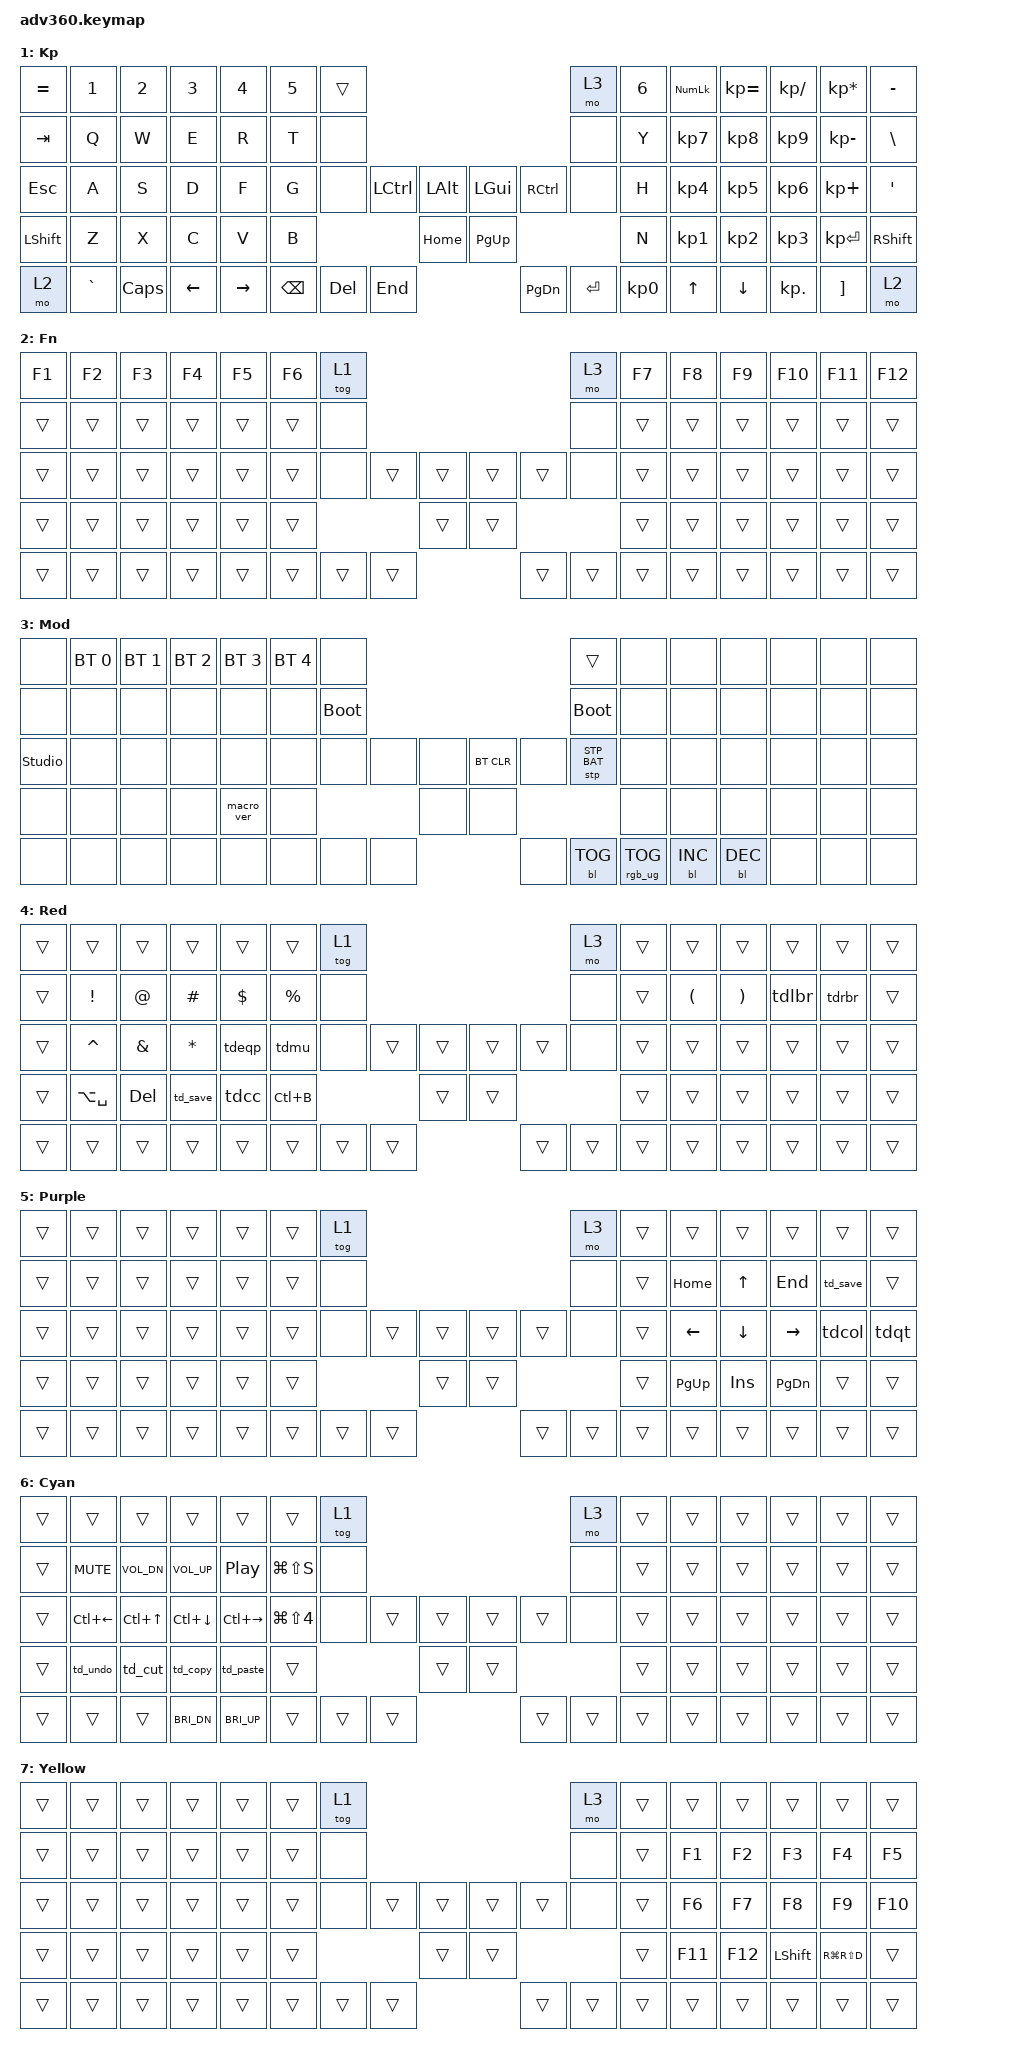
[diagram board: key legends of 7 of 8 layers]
#include <behaviors.dtsi>
#include <dt-bindings/zmk/keys.h>
#include <dt-bindings/zmk/bt.h>
#include <dt-bindings/zmk/rgb.h>
#include <dt-bindings/zmk/stp.h>
#include <dt-bindings/zmk/backlight.h>
#include <dt-bindings/zmk/pointing.h>

// Home row mods macro
#define HRML(k1,k2,k3,k4) &ht LALT k1  &ht LCTRL k2  &ht LGUI k3  &ht LSHFT k4
#define HRMR(k1,k2,k3,k4) &ht RSHFT k1  &ht RGUI k2  &ht LCTRL k3  &ht RALT k4

/ {
    behaviors {
      #include "macros.dtsi"
      #include "version.dtsi"

      hm: homerow_mods {
          compatible = "zmk,behavior-hold-tap";
          label = "HOMEROW_MODS";
          #binding-cells = <2>;
          tapping-term-ms = <200>;
          quick_tap_ms = <175>;
          flavor = "tap-preferred";
          bindings = <&kp>, <&kp>;
      };
      ht: hold_tap {
        label = "hold_tap";
        compatible = "zmk,behavior-hold-tap";
        #binding-cells = <2>;
        flavor = "tap-preferred";
        tapping-term-ms = <200>;
        quick-tap-ms = <150>;
        global-quick-tap;
        bindings = <&kp>, <&kp>;
      };
      tdmu: tap_dance_mu {
            compatible = "zmk,behavior-tap-dance";
            label = "TAP_DANCE_MU";
            #binding-cells = <0>;
            tapping-term-ms = <200>;
            bindings = <&kp MINUS>, <&kp UNDER>;
      };
      tdeqp: tap_dance_eqp {
        compatible = "zmk,behavior-tap-dance";
        label = "TAP_DANCE_EQP";
        #binding-cells = <0>;
        tapping-term-ms = <200>;
        bindings = <&kp EQUAL>, <&kp PLUS>;
      };
      tdlbr: tap_dance_lbr {
        compatible = "zmk,behavior-tap-dance";
        label = "TAP_DANCE_LBR";
        #binding-cells = <0>;
        tapping-term-ms = <200>;
        bindings = <&kp LBKT>, <&kp LBRC>;
      };
      tdrbr: tap_dance_rbr {
        compatible = "zmk,behavior-tap-dance";
        label = "TAP_DANCE_RBR";
        #binding-cells = <0>;
        tapping-term-ms = <200>;
        bindings = <&kp RBKT>, <&kp RBRC>;
      };
      tdcol: tap_dance_col {
        compatible = "zmk,behavior-tap-dance";
        label = "TAP_DANCE_COL";
        #binding-cells = <0>;
        tapping-term-ms = <200>;
        bindings = <&kp SEMI>, <&kp COLON>;
      };
      tdqt: tap_dance_qt {
        compatible = "zmk,behavior-tap-dance";
        label = "TAP_DANCE_QT";
        #binding-cells = <0>;
        tapping-term-ms = <200>;
        bindings = <&kp SQT>, <&kp DQT>;
      };
      tdgrv: tap_dance_grave {
        compatible = "zmk,behavior-tap-dance";
        label = "TAP_DANCE_GRAVE";
        #binding-cells = <0>;
        tapping-term-ms = <200>;
        bindings = <&kp H>, <&kp GRAVE>;
      };
      td_copy: tap_dance_copy {
        compatible = "zmk,behavior-tap-dance";
        label = "TAP_DANCE_COPY";
        #binding-cells = <0>;
        tapping-term-ms = <200>;
        bindings = <&kp LC(C)>, <&kp LG(C)>;
      };
      td_paste: tap_dance_paste {
        compatible = "zmk,behavior-tap-dance";
        label = "TAP_DANCE_PASTE";
        #binding-cells = <0>;
        tapping-term-ms = <200>;
        bindings = <&kp LC(V)>, <&kp LG(V)>;
      };
      td_undo: tap_dance_undo {
        compatible = "zmk,behavior-tap-dance";
        label = "TAP_DANCE_UNDO";
        #binding-cells = <0>;
        tapping-term-ms = <200>;
        bindings = <&kp LC(Z)>, <&kp LG(Z)>;
      };
      td_cut: tap_dance_cut {
        compatible = "zmk,behavior-tap-dance";
        label = "TAP_DANCE_CUT";
        #binding-cells = <0>;
        tapping-term-ms = <200>;
        bindings = <&kp LC(X)>, <&kp LG(X)>;
      };
      td_save: tap_dance_save{
        compatible = "zmk,behavior-tap-dance";
        label = "TAP_DANCE_SAVE";
        #binding-cells = <0>;
        tapping-term-ms = <200>;
        bindings = <&kp LC(S)>, <&kp LG(S)>;
      };
      tdcc: tap_dance_comment{
        compatible = "zmk,behavior-tap-dance";
        label = "TAP_DANCE_COMMENT"; 
        #binding-cells = <0>;
        tapping-term-ms = <200>;
        bindings = <&kp LC(SLASH)>, <&kp LG(SLASH)>;
      };
      td_win_right: tap_dance_window_right {
        compatible = "zmk,behavior-tap-dance";
        label = "TAP_DANCE_WINDOW_RIGHT"; 
        #binding-cells = <0>;
        tapping-term-ms = <200>;
        bindings = <&kp RIGHT>, <&kp LG(LC(RIGHT))>;
      };
      td_win_left: tap_dance_window_left {
        compatible = "zmk,behavior-tap-dance";
        label = "TAP_DANCE_WINDOW_LEFT"; 
        #binding-cells = <0>;
        tapping-term-ms = <200>;
        bindings = <&kp LEFT>, <&kp LG(LC(LEFT))>;
      };
    };

  keymap {
    compatible = "zmk,keymap";

    default_layer {
      display-name = "Base";
      bindings = <
        &kp EQUAL &kp N1    &kp N2   &kp N3       &kp N4     &kp N5 &tog 1                                                                   &mo 3 &kp N6 &kp N7 &kp N8    &kp N9   &kp N0   &kp MINUS
        &kp TAB   &kp Q     &kp W    &kp E        &kp R      &kp T  &none                                                                    &none &kp Y  &kp U  &kp I     &kp O    &kp P    &kp BSLH
        &kp ESC   HRML(A,       S,       D,           F)     &kp G  &kp LA(SPACE)     &kp LCTRL   &kp LALT &kp LGUI  &kp RCTRL               &none &tdgrv HRMR(J,    K,        L,      SEMI) &kp SQT
        &kp LSHFT &kp Z     &kp X    &kp C        &kp V      &kp B                                &kp HOME &kp PG_UP                               &kp N  &kp M  &kp COMMA &kp DOT  &kp FSLH &kp RSHFT
        &mo 2     &kp GRAVE &kp CAPS &td_win_left &td_win_right                 &lt 4 TAB &lt 6 ENTER &kp DEL  &kp PG_DN &lt 7 BSPC &lt 5 SPACE               &kp UP &kp DOWN  &kp LBKT &kp RBKT &mo 2
      >;
    };
    keypad {
      display-name = "Kp";
      bindings = <
        &kp EQUAL &kp N1    &kp N2   &kp N3   &kp N4     &kp N5 &trans                                                           &mo 3 &kp N6 &kp KP_NUM &kp KP_EQUAL &kp KP_DIVIDE &kp KP_MULTIPLY &kp MINUS
        &kp TAB   &kp Q     &kp W    &kp E    &kp R      &kp T  &none                                                            &none &kp Y  &kp KP_N7  &kp KP_N8    &kp KP_N9     &kp KP_MINUS    &kp BSLH
        &kp ESC   &kp A     &kp S    &kp D    &kp F      &kp G  &none           &kp LCTRL &kp LALT &kp LGUI  &kp RCTRL           &none &kp H  &kp KP_N4  &kp KP_N5    &kp KP_N6     &kp KP_PLUS     &kp SQT
        &kp LSHFT &kp Z     &kp X    &kp C    &kp V      &kp B                            &kp HOME &kp PG_UP                           &kp N  &kp KP_N1  &kp KP_N2    &kp KP_N3     &kp KP_ENTER    &kp RSHFT
        &mo 2     &kp GRAVE &kp CAPS &kp LEFT &kp RIGHT                &kp BSPC &kp DEL   &kp END  &kp PG_DN &kp ENTER &kp KP_N0              &kp UP     &kp DOWN     &kp KP_DOT    &kp RBKT        &mo 2
      >;
    };
    fn {
      display-name = "Fn";
      bindings = <
        &kp F1 &kp F2 &kp F3 &kp F4 &kp F5 &kp F6 &tog 1                                           &mo 3 &kp F7 &kp F8 &kp F9 &kp F10 &kp F11 &kp F12
        &trans &trans &trans &trans &trans &trans  &none                                           &none &trans &trans &trans &trans  &trans  &trans
        &trans &trans &trans &trans &trans &trans  &none        &trans &trans &trans &trans        &none &trans &trans &trans &trans  &trans  &trans
        &trans &trans &trans &trans &trans &trans                      &trans &trans                     &trans &trans &trans &trans  &trans  &trans
        &trans &trans &trans &trans &trans               &trans &trans &trans &trans &trans &trans              &trans &trans &trans  &trans  &trans
      >;
    };
    mod {
      display-name = "Mod";
      bindings = <
        &none &bt BT_SEL 0 &bt BT_SEL 1 &bt BT_SEL 2 &bt BT_SEL 3 &bt BT_SEL 4 &none                                                                     &trans                 &none        &none        &none        &none &none &none
        &none &none        &none        &none        &none        &none        &bootloader                                                               &bootloader            &none        &none        &none        &none &none &none
        &studio_unlock &none        &none        &none        &none        &none        &none                   &none &none &bt BT_CLR &none                      &stp STP_BAT &none        &none        &none        &none &none &none
        &none &none        &none        &none        &macro_ver   &none                                      &none &none                                                        &none        &none        &none        &none &none &none
        &none &none        &none        &none        &none                                       &none &none &none &none      &bl BL_TOG &rgb_ug RGB_TOG                                     &bl BL_INC   &bl BL_DEC   &none &none &none
      >;
    };

    // LAYER 4
    extra1 { 
      display-name = "Red";    
      bindings = <
        &trans &trans        &trans   &trans      &trans        &trans    &tog 1                                           &mo 3 &trans &trans   &trans   &trans &trans  &trans
        &trans &kp EXCL      &kp AT   &kp HASH    &kp DLLR      &kp PRCNT &none                                            &none &trans &kp LPAR &kp RPAR &tdlbr &tdrbr  &trans
        &trans &kp CARET     &kp AMPS &kp ASTRK   &tdeqp        &tdmu     &none          &trans &trans &trans &trans       &none &trans &trans   &trans   &trans &trans  &trans
        &trans &kp LA(SPACE) &kp DEL  &td_save    &tdcc         &kp LC(B)                        &trans &trans                   &trans &trans   &trans   &trans &trans  &trans
        &trans &trans        &trans   &trans      &trans                          &trans &trans &trans &trans &trans &trans             &trans   &trans   &trans &trans  &trans
      >;
    };

    // LAYER 5
    extra2 { 
      display-name = "Purple";    
      bindings = <
        &trans &trans &trans &trans &trans &trans  &tog 1                                          &mo 3 &trans &trans    &trans   &trans     &trans   &trans
        &trans &trans &trans &trans &trans &trans  &none                                           &none &trans &kp HOME  &kp UP   &kp END    &td_save &trans
        &trans &trans &trans &trans &trans &trans  &none        &trans &trans &trans &trans        &none &trans &kp LEFT  &kp DOWN &kp RIGHT  &tdcol   &tdqt
        &trans &trans &trans &trans &trans &trans                      &trans &trans                     &trans &kp PG_UP &kp INS  &kp PG_DN  &trans   &trans
        &trans &trans &trans &trans &trans               &trans &trans &trans &trans &trans &trans              &trans    &trans   &trans     &trans   &trans
      >;
    };

    // LAYER 6
    extra3 { 
      display-name = "Cyan";    
      bindings = <
        &trans &trans       &trans       &trans        &trans        &trans        &tog 1                                             &mo 3 &trans &trans  &trans   &trans     &trans   &trans
        &trans &kp C_MUTE   &kp C_VOL_DN &kp C_VOL_UP  &kp C_PP      &kp LG(LS(S)) &none                                              &none &trans &trans  &trans   &trans     &trans   &trans
        &trans &kp LC(LEFT) &kp LC(UP)   &kp LC(DOWN)  &kp LC(RIGHT) &kp LG(LS(4)) &none           &trans &trans &trans &trans        &none &trans &trans  &trans   &trans     &trans   &trans
        &trans &td_undo     &td_cut      &td_copy      &td_paste     &trans                               &trans &trans                     &trans &trans  &trans   &trans     &trans   &trans
        &trans &trans       &trans       &kp C_BRI_DN  &kp C_BRI_UP                         &trans &trans &trans &trans &trans &trans              &trans  &trans   &trans     &trans   &trans
      >;
    };

    // LAYER 7
    extra4 { 
      display-name = "Yellow";    
      bindings = <
        &trans &trans &trans &trans &trans &trans  &tog 1                                          &mo 3 &trans &trans  &trans  &trans    &trans        &trans
        &trans &trans &trans &trans &trans &trans  &none                                           &none &trans &kp F1  &kp F2  &kp F3    &kp F4        &kp F5
        &trans &trans &trans &trans &trans &trans  &none        &trans &trans &trans &trans        &none &trans &kp F6  &kp F7  &kp F8    &kp F9        &kp F10
        &trans &trans &trans &trans &trans &trans                      &trans &trans                     &trans &kp F11 &kp F12 &kp LSHFT &kp RG(RS(D)) &trans
        &trans &trans &trans &trans &trans               &trans &trans &trans &trans &trans &trans              &trans  &trans  &trans    &trans        &trans
      >;
    };
  };
};
